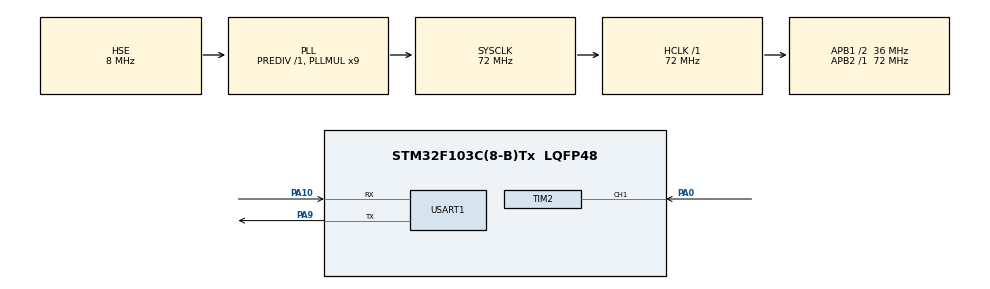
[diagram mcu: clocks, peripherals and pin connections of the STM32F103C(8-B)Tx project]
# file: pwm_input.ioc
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Mcu.Family=STM32F1
Mcu.Name=STM32F103C(8-B)Tx
Mcu.Package=LQFP48
NVIC.PriorityGroup=NVIC_PRIORITYGROUP_4
NVIC.TIM2_IRQn=true\:0\:0\:false\:false\:true\:true\:true
PA0-WKUP.Signal=S_TIM2_CH1_ETR
PA10.Mode=Asynchronous
PA10.Signal=USART1_RX
PA13.Mode=Serial_Wire
PA13.Signal=SYS_JTMS-SWDIO
PA14.Mode=Serial_Wire
PA14.Signal=SYS_JTCK-SWCLK
PA9.Mode=Asynchronous
PA9.Signal=USART1_TX
PD0-OSC_IN.Mode=HSE-External-Oscillator
PD0-OSC_IN.Signal=RCC_OSC_IN
PD1-OSC_OUT.Mode=HSE-External-Oscillator
PD1-OSC_OUT.Signal=RCC_OSC_OUT
ProjectManager.HeapSize=0x200
ProjectManager.StackSize=0x400
ProjectManager.TargetToolchain=MDK-ARM V5
RCC.AHBFreq_Value=72000000
RCC.APB1CLKDivider=RCC_HCLK_DIV2
RCC.APB1Freq_Value=36000000
RCC.APB1TimFreq_Value=72000000
RCC.APB2Freq_Value=72000000
RCC.APB2TimFreq_Value=72000000
RCC.HCLKFreq_Value=72000000
RCC.PLLMUL=RCC_PLL_MUL9
RCC.PLLSourceVirtual=RCC_PLLSOURCE_HSE
RCC.SYSCLKFreq_VALUE=72000000
RCC.SYSCLKSource=RCC_SYSCLKSOURCE_PLLCLK
RCC.USBFreq_Value=72000000
SH.S_TIM2_CH1_ETR.0=TIM2_CH1,PWM_Input_1
TIM2.ICPolarity_1=TIM_INPUTCHANNELPOLARITY_FALLING
TIM2.Period=50000
TIM2.Prescaler=720-1
USART1.VirtualMode=VM_ASYNC
board=custom

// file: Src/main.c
/* USER CODE BEGIN Header */
/**
  ******************************************************************************
  * @file           : main.c
  * @brief          : Main program body
  ******************************************************************************
  * @attention
  *
  * <h2><center>&copy; Copyright (c) 2020 STMicroelectronics.
  * All rights reserved.</center></h2>
  *
  * This software component is licensed by ST under BSD 3-Clause license,
  * the "License"; You may not use this file except in compliance with the
  * License. You may obtain a copy of the License at:
  *                        opensource.org/licenses/BSD-3-Clause
  *
  ******************************************************************************
  */
/* USER CODE END Header */

#include "main.h"

TIM_HandleTypeDef htim2;

UART_HandleTypeDef huart1;

void SystemClock_Config(void);
static void MX_GPIO_Init(void);
static void MX_TIM2_Init(void);
static void MX_USART1_UART_Init(void);

/* USER CODE BEGIN 0 */

/* Private user code ---------------------------------------------------------*/
/* USER CODE BEGIN 0 */
#include "stdio.h"

int fputc(int ch, FILE *f)
{
    HAL_UART_Transmit(&huart1, (uint8_t *)&ch,1, 0xFFFF);
    return ch;
}

unsigned int RxData = 0xFF;	//接收数据
int RxOk = 0;				//接收标志位

/* 捕获回调函数 */
void HAL_TIM_IC_CaptureCallback(TIM_HandleTypeDef *htim)
{
	static uint32_t m_pulse;
//	if(htim->Channel == HAL_TIM_ACTIVE_CHANNEL_1)
//	{
//		/* 得到周期 */
//		m_period = HAL_TIM_ReadCapturedValue(&htim2, TIM_CHANNEL_1);//低电平加高电平时间
//	}
	if (htim->Channel == HAL_TIM_ACTIVE_CHANNEL_2)
    {
		m_pulse = HAL_TIM_ReadCapturedValue(&htim2, TIM_CHANNEL_2);	//得到低电平的时间
		printf("m_pulse is %d\n",m_pulse);
		//add_low_level(m_pulse, &RxData);									//获取数据
    }
}

/* USER CODE END 0 */

int main(void)
{

  /* MCU Configuration--------------------------------------------------------*/

  /* Reset of all peripherals, Initializes the Flash interface and the Systick. */
  HAL_Init();

  /* Configure the system clock */
  SystemClock_Config();

  /* Initialize all configured peripherals */
  MX_GPIO_Init();
  MX_TIM2_Init();
  MX_USART1_UART_Init();
  /* USER CODE BEGIN 2 */

  HAL_TIM_IC_Start_IT(&htim2,TIM_CHANNEL_2);
  /* USER CODE END 2 */

  /* Infinite loop */
  while (1)
  {

    /* USER CODE BEGIN 3 */
	  	//printf("m_pulse is %d\n");

  }
  /* USER CODE END 3 */
}

void SystemClock_Config(void)
{
  RCC_OscInitTypeDef RCC_OscInitStruct = {0};
  RCC_ClkInitTypeDef RCC_ClkInitStruct = {0};

  /** Initializes the CPU, AHB and APB busses clocks
  */
  RCC_OscInitStruct.OscillatorType = RCC_OSCILLATORTYPE_HSE;
  RCC_OscInitStruct.HSEState = RCC_HSE_ON;
  RCC_OscInitStruct.HSEPredivValue = RCC_HSE_PREDIV_DIV1;
  RCC_OscInitStruct.HSIState = RCC_HSI_ON;
  RCC_OscInitStruct.PLL.PLLState = RCC_PLL_ON;
  RCC_OscInitStruct.PLL.PLLSource = RCC_PLLSOURCE_HSE;
  RCC_OscInitStruct.PLL.PLLMUL = RCC_PLL_MUL9;
  if (HAL_RCC_OscConfig(&RCC_OscInitStruct) != HAL_OK)
  {
    Error_Handler();
  }
  /** Initializes the CPU, AHB and APB busses clocks
  */
  RCC_ClkInitStruct.ClockType = RCC_CLOCKTYPE_HCLK|RCC_CLOCKTYPE_SYSCLK
                              |RCC_CLOCKTYPE_PCLK1|RCC_CLOCKTYPE_PCLK2;
  RCC_ClkInitStruct.SYSCLKSource = RCC_SYSCLKSOURCE_PLLCLK;
  RCC_ClkInitStruct.AHBCLKDivider = RCC_SYSCLK_DIV1;
  RCC_ClkInitStruct.APB1CLKDivider = RCC_HCLK_DIV2;
  RCC_ClkInitStruct.APB2CLKDivider = RCC_HCLK_DIV1;

  if (HAL_RCC_ClockConfig(&RCC_ClkInitStruct, FLASH_LATENCY_2) != HAL_OK)
  {
    Error_Handler();
  }
}

static void MX_TIM2_Init(void)
{

  TIM_SlaveConfigTypeDef sSlaveConfig = {0};
  TIM_IC_InitTypeDef sConfigIC = {0};
  TIM_MasterConfigTypeDef sMasterConfig = {0};

  htim2.Instance = TIM2;
  htim2.Init.Prescaler = 720-1;
  htim2.Init.CounterMode = TIM_COUNTERMODE_UP;
  htim2.Init.Period = 50000;
  htim2.Init.ClockDivision = TIM_CLOCKDIVISION_DIV1;
  htim2.Init.AutoReloadPreload = TIM_AUTORELOAD_PRELOAD_DISABLE;
  if (HAL_TIM_IC_Init(&htim2) != HAL_OK)
  {
    Error_Handler();
  }
  sSlaveConfig.SlaveMode = TIM_SLAVEMODE_RESET;
  sSlaveConfig.InputTrigger = TIM_TS_TI1FP1;
  sSlaveConfig.TriggerPolarity = TIM_INPUTCHANNELPOLARITY_FALLING;
  sSlaveConfig.TriggerPrescaler = TIM_ICPSC_DIV1;
  sSlaveConfig.TriggerFilter = 0;
  if (HAL_TIM_SlaveConfigSynchro(&htim2, &sSlaveConfig) != HAL_OK)
  {
    Error_Handler();
  }
  sConfigIC.ICPolarity = TIM_INPUTCHANNELPOLARITY_FALLING;
  sConfigIC.ICSelection = TIM_ICSELECTION_DIRECTTI;
  sConfigIC.ICPrescaler = TIM_ICPSC_DIV1;
  sConfigIC.ICFilter = 0;
  if (HAL_TIM_IC_ConfigChannel(&htim2, &sConfigIC, TIM_CHANNEL_1) != HAL_OK)
  {
    Error_Handler();
  }
  sConfigIC.ICPolarity = TIM_INPUTCHANNELPOLARITY_RISING;
  sConfigIC.ICSelection = TIM_ICSELECTION_INDIRECTTI;
  if (HAL_TIM_IC_ConfigChannel(&htim2, &sConfigIC, TIM_CHANNEL_2) != HAL_OK)
  {
    Error_Handler();
  }
  sMasterConfig.MasterOutputTrigger = TIM_TRGO_RESET;
  sMasterConfig.MasterSlaveMode = TIM_MASTERSLAVEMODE_DISABLE;
  if (HAL_TIMEx_MasterConfigSynchronization(&htim2, &sMasterConfig) != HAL_OK)
  {
    Error_Handler();
  }

}

static void MX_USART1_UART_Init(void)
{

  huart1.Instance = USART1;
  huart1.Init.BaudRate = 115200;
  huart1.Init.WordLength = UART_WORDLENGTH_8B;
  huart1.Init.StopBits = UART_STOPBITS_1;
  huart1.Init.Parity = UART_PARITY_NONE;
  huart1.Init.Mode = UART_MODE_TX_RX;
  huart1.Init.HwFlowCtl = UART_HWCONTROL_NONE;
  huart1.Init.OverSampling = UART_OVERSAMPLING_16;
  if (HAL_UART_Init(&huart1) != HAL_OK)
  {
    Error_Handler();
  }

}

static void MX_GPIO_Init(void)
{

  /* GPIO Ports Clock Enable */
  __HAL_RCC_GPIOD_CLK_ENABLE();
  __HAL_RCC_GPIOA_CLK_ENABLE();

}

void Error_Handler(void)
{
}

/************************ (C) COPYRIGHT STMicroelectronics *****END OF FILE****/
